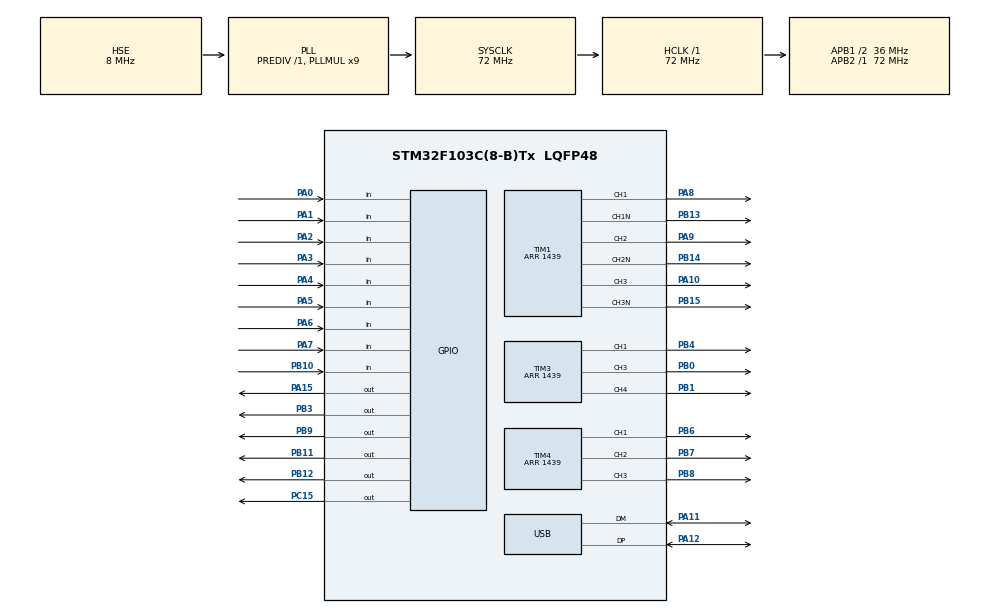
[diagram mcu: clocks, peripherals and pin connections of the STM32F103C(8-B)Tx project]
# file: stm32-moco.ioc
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Mcu.Family=STM32F1
Mcu.Name=STM32F103C(8-B)Tx
Mcu.Package=LQFP48
NVIC.PriorityGroup=NVIC_PRIORITYGROUP_4
NVIC.USB_LP_CAN1_RX0_IRQn=true\:0\:0\:false\:false\:true\:false\:true\:true
PA0-WKUP.GPIO_Mode=GPIO_MODE_INPUT
PA0-WKUP.GPIO_PuPd=GPIO_PULLUP
PA0-WKUP.Signal=GPIO_Input
PA1.GPIO_Mode=GPIO_MODE_INPUT
PA1.GPIO_PuPd=GPIO_PULLUP
PA1.Signal=GPIO_Input
PA10.Signal=S_TIM1_CH3
PA11.Mode=Device
PA11.Signal=USB_DM
PA12.Mode=Device
PA12.Signal=USB_DP
PA13.Mode=Serial_Wire
PA13.Signal=SYS_JTMS-SWDIO
PA14.Mode=Serial_Wire
PA14.Signal=SYS_JTCK-SWCLK
PA15.Signal=GPIO_Output
PA2.GPIO_Mode=GPIO_MODE_INPUT
PA2.GPIO_PuPd=GPIO_PULLUP
PA2.Signal=GPIO_Input
PA3.GPIO_Mode=GPIO_MODE_INPUT
PA3.GPIO_PuPd=GPIO_PULLUP
PA3.Signal=GPIO_Input
PA4.GPIO_Mode=GPIO_MODE_INPUT
PA4.GPIO_PuPd=GPIO_PULLUP
PA4.Signal=GPIO_Input
PA5.GPIO_Mode=GPIO_MODE_INPUT
PA5.GPIO_PuPd=GPIO_PULLUP
PA5.Signal=GPIO_Input
PA6.Signal=GPIO_Input
PA7.Signal=GPIO_Input
PA8.Signal=S_TIM1_CH1
PA9.Signal=S_TIM1_CH2
PB0.Signal=S_TIM3_CH3
PB1.Signal=S_TIM3_CH4
PB10.GPIO_Mode=GPIO_MODE_INPUT
PB10.GPIO_PuPd=GPIO_PULLUP
PB10.Signal=GPIO_Input
PB11.Signal=GPIO_Output
PB12.Signal=GPIO_Output
PB13.Mode=PWM Generation1 CH1 CH1N
PB13.Signal=TIM1_CH1N
PB14.Mode=PWM Generation2 CH2 CH2N
PB14.Signal=TIM1_CH2N
PB15.Mode=PWM Generation3 CH3 CH3N
PB15.Signal=TIM1_CH3N
PB3.Signal=GPIO_Output
PB4.Signal=S_TIM3_CH1
PB6.Signal=S_TIM4_CH1
PB7.Signal=S_TIM4_CH2
PB8.Signal=S_TIM4_CH3
PB9.Signal=GPIO_Output
PC15-OSC32_OUT.Signal=GPIO_Output
PD0-OSC_IN.Mode=HSE-External-Oscillator
PD0-OSC_IN.Signal=RCC_OSC_IN
PD1-OSC_OUT.Mode=HSE-External-Oscillator
PD1-OSC_OUT.Signal=RCC_OSC_OUT
ProjectManager.HeapSize=0x200
ProjectManager.StackSize=0x400
ProjectManager.TargetToolchain=STM32CubeIDE
RCC.AHBFreq_Value=72000000
RCC.APB1CLKDivider=RCC_HCLK_DIV2
RCC.APB1Freq_Value=36000000
RCC.APB1TimFreq_Value=72000000
RCC.APB2Freq_Value=72000000
RCC.APB2TimFreq_Value=72000000
RCC.HCLKFreq_Value=72000000
RCC.PLLMUL=RCC_PLL_MUL9
RCC.PLLSourceVirtual=RCC_PLLSOURCE_HSE
RCC.SYSCLKFreq_VALUE=72000000
RCC.SYSCLKSource=RCC_SYSCLKSOURCE_PLLCLK
RCC.USBFreq_Value=48000000
RCC.USBPrescaler=RCC_USBCLKSOURCE_PLL_DIV1_5
SH.S_TIM1_CH1.0=TIM1_CH1,PWM Generation1 CH1 CH1N
SH.S_TIM1_CH2.0=TIM1_CH2,PWM Generation2 CH2 CH2N
SH.S_TIM1_CH3.0=TIM1_CH3,PWM Generation3 CH3 CH3N
SH.S_TIM3_CH1.0=TIM3_CH1,PWM Generation1 CH1
SH.S_TIM3_CH3.0=TIM3_CH3,PWM Generation3 CH3
SH.S_TIM3_CH4.0=TIM3_CH4,PWM Generation4 CH4
SH.S_TIM4_CH1.0=TIM4_CH1,PWM Generation1 CH1
SH.S_TIM4_CH2.0=TIM4_CH2,PWM Generation2 CH2
SH.S_TIM4_CH3.0=TIM4_CH3,PWM Generation3 CH3
TIM1.Channel-PWM\ Generation1\ CH1\ CH1N=TIM_CHANNEL_1
TIM1.Channel-PWM\ Generation2\ CH2\ CH2N=TIM_CHANNEL_2
TIM1.Channel-PWM\ Generation3\ CH3\ CH3N=TIM_CHANNEL_3
TIM1.Period=1439
TIM3.Channel-PWM\ Generation1\ CH1=TIM_CHANNEL_1
TIM3.Channel-PWM\ Generation3\ CH3=TIM_CHANNEL_3
TIM3.Channel-PWM\ Generation4\ CH4=TIM_CHANNEL_4
TIM3.Period=1439
TIM4.Channel-PWM\ Generation1\ CH1=TIM_CHANNEL_1
TIM4.Channel-PWM\ Generation2\ CH2=TIM_CHANNEL_2
TIM4.Channel-PWM\ Generation3\ CH3=TIM_CHANNEL_3
TIM4.Period=1439
USB_DEVICE.CLASS_NAME_FS=CDC
USB_DEVICE.VirtualMode=Cdc
USB_DEVICE.VirtualModeFS=Cdc_FS
VP_TIM1_VS_ClockSourceINT.Mode=Internal
VP_USB_DEVICE_VS_USB_DEVICE_CDC_FS.Mode=CDC_FS
board=custom

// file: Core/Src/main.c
/* USER CODE BEGIN Header */
/**
  ******************************************************************************
  * @file           : main.c
  * @brief          : Main program body – stm32-moco motor controller
  ******************************************************************************
  * @attention
  *
  * Copyright (c) 2026 STMicroelectronics.
  * All rights reserved.
  *
  * This software is licensed under terms that can be found in the LICENSE file
  * in the root directory of this software component.
  * If no LICENSE file comes with this software, it is provided AS-IS.
  *
  ******************************************************************************
  */
/* USER CODE END Header */
#include "main.h"
#include "usb_device.h"

/* USER CODE BEGIN Includes */
#include "motor_ctrl.h"
#include "usb_cmd.h"
/* USER CODE END Includes */

TIM_HandleTypeDef htim1;
TIM_HandleTypeDef htim3;
TIM_HandleTypeDef htim4;

void SystemClock_Config(void);
static void MX_GPIO_Init(void);
static void MX_TIM1_Init(void);
static void MX_TIM3_Init(void);
static void MX_TIM4_Init(void);

int main(void)
{

  /* USER CODE BEGIN 1 */
  /* NOTE: All motor outputs will be driven LOW by Motor_Init() before
   *       any commutation begins – safe default at power-on. */
  /* USER CODE END 1 */

  /* MCU Configuration--------------------------------------------------------*/

  /* Reset of all peripherals, Initializes the Flash interface and the Systick. */
  HAL_Init();

  /* Configure the system clock */
  SystemClock_Config();

  /* Initialize all configured peripherals */
  MX_GPIO_Init();
  MX_TIM1_Init();
  MX_TIM3_Init();
  MX_TIM4_Init();
  MX_USB_DEVICE_Init();
  /* USER CODE BEGIN 2 */

  /* Initialise motor controller – all outputs default LOW (safe) */
  Motor_Init();

  /* Allow USB CDC to enumerate before sending the welcome message */
  HAL_Delay(500);

  /* Initialise USB command shell */
  USBCMD_Init();

  /* USER CODE END 2 */

  /* Infinite loop */
  while (1)
  {

    /* USER CODE BEGIN 3 */

    /* Motor_CommutateAll() is called exclusively from SysTick_Handler
     * (1 kHz). Calling it here as well would create a race condition
     * where the ISR updates hall_state mid-step and the main loop
     * resumes with a stale new_hall, producing jitter and wrong PWM
     * (Bug 1 fix – removed from here). */

    /* Process any pending USB CDC commands from the Atomic Pi */
    USBCMD_Process();

    /* Stall detection – check every ~10ms */
    {
        static uint32_t last_sc = 0;
        uint32_t now = HAL_GetTick();
        if (now - last_sc >= 10) {
            last_sc = now;
            for (uint8_t m = 0; m < MOTOR_COUNT; m++)
                Motor_CheckStall(m, now);
        }
    }

  }
  /* USER CODE END 3 */
}

void SystemClock_Config(void)
{
  RCC_OscInitTypeDef RCC_OscInitStruct = {0};
  RCC_ClkInitTypeDef RCC_ClkInitStruct = {0};
  RCC_PeriphCLKInitTypeDef PeriphClkInit = {0};

  /** Initializes the RCC Oscillators according to the specified parameters
  * in the RCC_OscInitTypeDef structure.
  */
  RCC_OscInitStruct.OscillatorType = RCC_OSCILLATORTYPE_HSE;
  RCC_OscInitStruct.HSEState = RCC_HSE_ON;
  RCC_OscInitStruct.HSEPredivValue = RCC_HSE_PREDIV_DIV1;
  RCC_OscInitStruct.HSIState = RCC_HSI_ON;
  RCC_OscInitStruct.PLL.PLLState = RCC_PLL_ON;
  RCC_OscInitStruct.PLL.PLLSource = RCC_PLLSOURCE_HSE;
  RCC_OscInitStruct.PLL.PLLMUL = RCC_PLL_MUL9;
  if (HAL_RCC_OscConfig(&RCC_OscInitStruct) != HAL_OK)
  {
    Error_Handler();
  }

  /** Initializes the CPU, AHB and APB buses clocks
  */
  RCC_ClkInitStruct.ClockType = RCC_CLOCKTYPE_HCLK|RCC_CLOCKTYPE_SYSCLK
                              |RCC_CLOCKTYPE_PCLK1|RCC_CLOCKTYPE_PCLK2;
  RCC_ClkInitStruct.SYSCLKSource = RCC_SYSCLKSOURCE_PLLCLK;
  RCC_ClkInitStruct.AHBCLKDivider = RCC_SYSCLK_DIV1;
  RCC_ClkInitStruct.APB1CLKDivider = RCC_HCLK_DIV2;
  RCC_ClkInitStruct.APB2CLKDivider = RCC_HCLK_DIV1;

  if (HAL_RCC_ClockConfig(&RCC_ClkInitStruct, FLASH_LATENCY_2) != HAL_OK)
  {
    Error_Handler();
  }
  PeriphClkInit.PeriphClockSelection = RCC_PERIPHCLK_USB;
  PeriphClkInit.UsbClockSelection = RCC_USBCLKSOURCE_PLL_DIV1_5;
  if (HAL_RCCEx_PeriphCLKConfig(&PeriphClkInit) != HAL_OK)
  {
    Error_Handler();
  }
}

static void MX_TIM1_Init(void)
{

  TIM_ClockConfigTypeDef sClockSourceConfig = {0};
  TIM_MasterConfigTypeDef sMasterConfig = {0};
  TIM_OC_InitTypeDef sConfigOC = {0};
  TIM_BreakDeadTimeConfigTypeDef sBreakDeadTimeConfig = {0};

  htim1.Instance = TIM1;
  htim1.Init.Prescaler = 0;
  htim1.Init.CounterMode = TIM_COUNTERMODE_UP;
  htim1.Init.Period = 1439;
  htim1.Init.ClockDivision = TIM_CLOCKDIVISION_DIV1;
  htim1.Init.RepetitionCounter = 0;
  htim1.Init.AutoReloadPreload = TIM_AUTORELOAD_PRELOAD_DISABLE;
  if (HAL_TIM_Base_Init(&htim1) != HAL_OK)
  {
    Error_Handler();
  }
  sClockSourceConfig.ClockSource = TIM_CLOCKSOURCE_INTERNAL;
  if (HAL_TIM_ConfigClockSource(&htim1, &sClockSourceConfig) != HAL_OK)
  {
    Error_Handler();
  }
  if (HAL_TIM_PWM_Init(&htim1) != HAL_OK)
  {
    Error_Handler();
  }
  sMasterConfig.MasterOutputTrigger = TIM_TRGO_RESET;
  sMasterConfig.MasterSlaveMode = TIM_MASTERSLAVEMODE_DISABLE;
  if (HAL_TIMEx_MasterConfigSynchronization(&htim1, &sMasterConfig) != HAL_OK)
  {
    Error_Handler();
  }
  sConfigOC.OCMode = TIM_OCMODE_PWM1;
  sConfigOC.Pulse = 0;
  sConfigOC.OCPolarity = TIM_OCPOLARITY_HIGH;
  sConfigOC.OCNPolarity = TIM_OCNPOLARITY_HIGH;
  sConfigOC.OCFastMode = TIM_OCFAST_DISABLE;
  sConfigOC.OCIdleState = TIM_OCIDLESTATE_RESET;
  sConfigOC.OCNIdleState = TIM_OCNIDLESTATE_RESET;
  if (HAL_TIM_PWM_ConfigChannel(&htim1, &sConfigOC, TIM_CHANNEL_1) != HAL_OK)
  {
    Error_Handler();
  }
  if (HAL_TIM_PWM_ConfigChannel(&htim1, &sConfigOC, TIM_CHANNEL_2) != HAL_OK)
  {
    Error_Handler();
  }
  if (HAL_TIM_PWM_ConfigChannel(&htim1, &sConfigOC, TIM_CHANNEL_3) != HAL_OK)
  {
    Error_Handler();
  }
  sBreakDeadTimeConfig.OffStateRunMode = TIM_OSSR_DISABLE;
  sBreakDeadTimeConfig.OffStateIDLEMode = TIM_OSSI_DISABLE;
  sBreakDeadTimeConfig.LockLevel = TIM_LOCKLEVEL_OFF;
  sBreakDeadTimeConfig.DeadTime = 4;
  sBreakDeadTimeConfig.BreakState = TIM_BREAK_DISABLE;
  sBreakDeadTimeConfig.BreakPolarity = TIM_BREAKPOLARITY_HIGH;
  sBreakDeadTimeConfig.AutomaticOutput = TIM_AUTOMATICOUTPUT_DISABLE;
  if (HAL_TIMEx_ConfigBreakDeadTime(&htim1, &sBreakDeadTimeConfig) != HAL_OK)
  {
    Error_Handler();
  }
  /* USER CODE BEGIN TIM1_Init 2 */
  /* Override BDTR after CubeMX init: enable OSSR+OSSI so TIM1 complementary
   * outputs (PB13/14/15 = M1LSA/B/C) are forced LOW when MOE is off.
   * Without this they float/latch high at idle.
   * AutomaticOutput=DISABLE ensures MOE can only be re-enabled explicitly
   * via __HAL_TIM_MOE_ENABLE – Motor_SafeAll()/all_off() cannot be
   * circumvented by hardware (Bug 3 fix).
   * Placed in USER CODE so CubeMX regeneration does not remove it. */
  sBreakDeadTimeConfig.OffStateRunMode  = TIM_OSSR_ENABLE;
  sBreakDeadTimeConfig.OffStateIDLEMode = TIM_OSSI_ENABLE;
  sBreakDeadTimeConfig.AutomaticOutput  = TIM_AUTOMATICOUTPUT_DISABLE;
  sBreakDeadTimeConfig.DeadTime         = 0;
  HAL_TIMEx_ConfigBreakDeadTime(&htim1, &sBreakDeadTimeConfig);
  /* OCNPolarity = TIM_OCNPOLARITY_HIGH is set above in sConfigOC (line 231).
   * Do NOT set CCxNP=1 here — TIM1 handles dead-time and complementary
   * logic in hardware, no polarity inversion needed. */
  /* USER CODE END TIM1_Init 2 */
  HAL_TIM_MspPostInit(&htim1);

}

static void MX_TIM3_Init(void)
{

  TIM_MasterConfigTypeDef sMasterConfig = {0};
  TIM_OC_InitTypeDef sConfigOC = {0};

  htim3.Instance = TIM3;
  htim3.Init.Prescaler = 0;
  htim3.Init.CounterMode = TIM_COUNTERMODE_UP;
  htim3.Init.Period = 1439;
  htim3.Init.ClockDivision = TIM_CLOCKDIVISION_DIV1;
  htim3.Init.AutoReloadPreload = TIM_AUTORELOAD_PRELOAD_DISABLE;
  if (HAL_TIM_PWM_Init(&htim3) != HAL_OK)
  {
    Error_Handler();
  }
  sMasterConfig.MasterOutputTrigger = TIM_TRGO_RESET;
  sMasterConfig.MasterSlaveMode = TIM_MASTERSLAVEMODE_DISABLE;
  if (HAL_TIMEx_MasterConfigSynchronization(&htim3, &sMasterConfig) != HAL_OK)
  {
    Error_Handler();
  }
  sConfigOC.OCMode = TIM_OCMODE_PWM1;
  sConfigOC.Pulse = 0;
  sConfigOC.OCPolarity = TIM_OCPOLARITY_HIGH;
  sConfigOC.OCFastMode = TIM_OCFAST_DISABLE;
  if (HAL_TIM_PWM_ConfigChannel(&htim3, &sConfigOC, TIM_CHANNEL_1) != HAL_OK)
  {
    Error_Handler();
  }
  if (HAL_TIM_PWM_ConfigChannel(&htim3, &sConfigOC, TIM_CHANNEL_3) != HAL_OK)
  {
    Error_Handler();
  }
  if (HAL_TIM_PWM_ConfigChannel(&htim3, &sConfigOC, TIM_CHANNEL_4) != HAL_OK)
  {
    Error_Handler();
  }
  HAL_TIM_MspPostInit(&htim3);

}

static void MX_TIM4_Init(void)
{

  TIM_MasterConfigTypeDef sMasterConfig = {0};
  TIM_OC_InitTypeDef sConfigOC = {0};

  htim4.Instance = TIM4;
  htim4.Init.Prescaler = 0;
  htim4.Init.CounterMode = TIM_COUNTERMODE_UP;
  htim4.Init.Period = 1439;
  htim4.Init.ClockDivision = TIM_CLOCKDIVISION_DIV1;
  htim4.Init.AutoReloadPreload = TIM_AUTORELOAD_PRELOAD_DISABLE;
  if (HAL_TIM_PWM_Init(&htim4) != HAL_OK)
  {
    Error_Handler();
  }
  sMasterConfig.MasterOutputTrigger = TIM_TRGO_RESET;
  sMasterConfig.MasterSlaveMode = TIM_MASTERSLAVEMODE_DISABLE;
  if (HAL_TIMEx_MasterConfigSynchronization(&htim4, &sMasterConfig) != HAL_OK)
  {
    Error_Handler();
  }
  sConfigOC.OCMode = TIM_OCMODE_PWM1;
  sConfigOC.Pulse = 0;
  sConfigOC.OCPolarity = TIM_OCPOLARITY_HIGH;
  sConfigOC.OCFastMode = TIM_OCFAST_DISABLE;
  if (HAL_TIM_PWM_ConfigChannel(&htim4, &sConfigOC, TIM_CHANNEL_1) != HAL_OK)
  {
    Error_Handler();
  }
  if (HAL_TIM_PWM_ConfigChannel(&htim4, &sConfigOC, TIM_CHANNEL_2) != HAL_OK)
  {
    Error_Handler();
  }
  if (HAL_TIM_PWM_ConfigChannel(&htim4, &sConfigOC, TIM_CHANNEL_3) != HAL_OK)
  {
    Error_Handler();
  }
  HAL_TIM_MspPostInit(&htim4);

}

static void MX_GPIO_Init(void)
{
  GPIO_InitTypeDef GPIO_InitStruct = {0};

  /* GPIO Ports Clock Enable */
  __HAL_RCC_GPIOC_CLK_ENABLE();
  __HAL_RCC_GPIOD_CLK_ENABLE();
  __HAL_RCC_GPIOA_CLK_ENABLE();
  __HAL_RCC_GPIOB_CLK_ENABLE();

  /*Configure GPIO pin Output Level */
  HAL_GPIO_WritePin(GPIOC, GPIO_PIN_15, GPIO_PIN_RESET);

  /*Configure GPIO pin Output Level - PB3=M2LSB, PB5=M2LSC, PB9=M3LSA, PB11=M3LSB, PB12=M3LSC */
  HAL_GPIO_WritePin(GPIOB, GPIO_PIN_3|GPIO_PIN_5|GPIO_PIN_9|GPIO_PIN_11|GPIO_PIN_12, GPIO_PIN_RESET);

  /*Configure GPIO pin Output Level - PA15=M2LSA */
  HAL_GPIO_WritePin(GPIOA, GPIO_PIN_15, GPIO_PIN_RESET);

  /*Configure GPIO pin : PC15 */
  GPIO_InitStruct.Pin = GPIO_PIN_15;
  GPIO_InitStruct.Mode = GPIO_MODE_OUTPUT_PP;
  GPIO_InitStruct.Pull = GPIO_NOPULL;
  GPIO_InitStruct.Speed = GPIO_SPEED_FREQ_LOW;
  HAL_GPIO_Init(GPIOC, &GPIO_InitStruct);

  /*Configure GPIO pins : PA0 PA1 PA2 PA3 PA4 PA5 (M1HA/HB/HC, M2HA/HB/HC Hall inputs) */
  GPIO_InitStruct.Pin = GPIO_PIN_0|GPIO_PIN_1|GPIO_PIN_2|GPIO_PIN_3
                          |GPIO_PIN_4|GPIO_PIN_5;
  GPIO_InitStruct.Mode = GPIO_MODE_INPUT;
  GPIO_InitStruct.Pull = GPIO_PULLUP;
  HAL_GPIO_Init(GPIOA, &GPIO_InitStruct);

  /*Configure GPIO pins : PA6 PA7 (M3HA, M3HB Hall inputs - fix: was NOPULL) */
  GPIO_InitStruct.Pin = GPIO_PIN_6|GPIO_PIN_7;
  GPIO_InitStruct.Mode = GPIO_MODE_INPUT;
  GPIO_InitStruct.Pull = GPIO_PULLUP;
  HAL_GPIO_Init(GPIOA, &GPIO_InitStruct);

  /*Configure GPIO pin : PB10 (M3HC Hall input) */
  GPIO_InitStruct.Pin = GPIO_PIN_10;
  GPIO_InitStruct.Mode = GPIO_MODE_INPUT;
  GPIO_InitStruct.Pull = GPIO_PULLUP;
  HAL_GPIO_Init(GPIOB, &GPIO_InitStruct);

  /*Configure GPIO pins : PB3 PB5 PB9 PB11 PB12 (low-side enables, plain GPIO output)
   * PB3=M2LSB, PB5=M2LSC, PB9=M3LSA, PB11=M3LSB, PB12=M3LSC */
  GPIO_InitStruct.Pin = GPIO_PIN_3|GPIO_PIN_5|GPIO_PIN_9|GPIO_PIN_11|GPIO_PIN_12;
  GPIO_InitStruct.Mode = GPIO_MODE_OUTPUT_PP;
  GPIO_InitStruct.Pull = GPIO_NOPULL;
  GPIO_InitStruct.Speed = GPIO_SPEED_FREQ_LOW;
  HAL_GPIO_Init(GPIOB, &GPIO_InitStruct);

  /*Configure GPIO pin : PA15 (M2LSA low-side enable, plain GPIO output) */
  GPIO_InitStruct.Pin = GPIO_PIN_15;
  GPIO_InitStruct.Mode = GPIO_MODE_OUTPUT_PP;
  GPIO_InitStruct.Pull = GPIO_NOPULL;
  GPIO_InitStruct.Speed = GPIO_SPEED_FREQ_LOW;
  HAL_GPIO_Init(GPIOA, &GPIO_InitStruct);

}

void Error_Handler(void)
{
  __disable_irq();
  while (1)
  {
  }
}
#ifdef USE_FULL_ASSERT
/**
  * @brief  Reports the name of the source file and the source line number
  *         where the assert_param error has occurred.
  * @param  file: pointer to the source file name
  * @param  line: assert_param error line source number
  */
void assert_failed(uint8_t *file, uint32_t line)
{
  /* USER CODE BEGIN 6 */
  (void)file; (void)line;
  /* USER CODE END 6 */
}
#endif /* USE_FULL_ASSERT */
